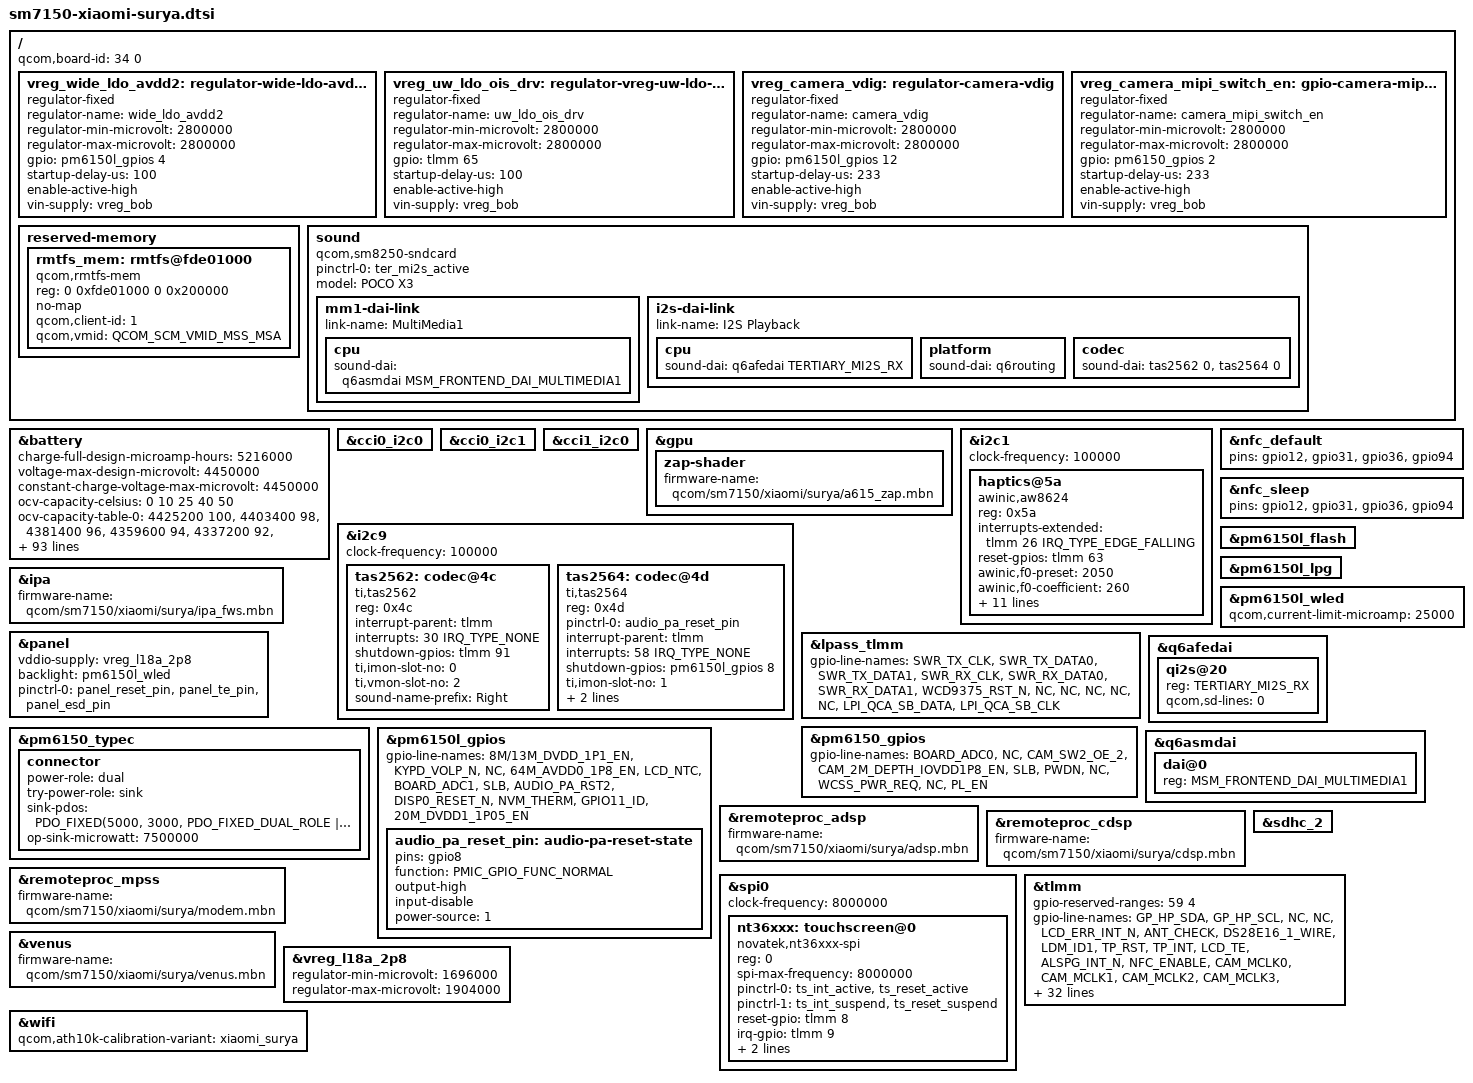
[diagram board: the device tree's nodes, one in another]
// SPDX-License-Identifier: BSD-3-Clause
/*
 * Copyright (c) 2024, Danila Tikhonov <danila@jiaxyga.com>
 * Copyright (c) 2024, David Wronek <davidwronek@gmail.com>
 */

/dts-v1/;

#include "sm7150-xiaomi-common.dtsi"

/ {
	qcom,board-id = <34 0>;

	vreg_wide_ldo_avdd2: regulator-wide-ldo-avdd2 {
		compatible = "regulator-fixed";
		regulator-name = "wide_ldo_avdd2";
		regulator-min-microvolt = <2800000>;
		regulator-max-microvolt = <2800000>;

		gpio = <&pm6150l_gpios 4 GPIO_ACTIVE_HIGH>;
		startup-delay-us = <100>;
		enable-active-high;

		vin-supply = <&vreg_bob>;
	};

	vreg_uw_ldo_ois_drv: regulator-vreg-uw-ldo-ois-drv {
		compatible = "regulator-fixed";
		regulator-name = "uw_ldo_ois_drv";
		regulator-min-microvolt = <2800000>;
		regulator-max-microvolt = <2800000>;

		gpio = <&tlmm 65 GPIO_ACTIVE_HIGH>;
		startup-delay-us = <100>;
		enable-active-high;

		vin-supply = <&vreg_bob>;
	};

	vreg_camera_vdig: regulator-camera-vdig {
		compatible = "regulator-fixed";
		regulator-name = "camera_vdig";
		regulator-min-microvolt = <2800000>;
		regulator-max-microvolt = <2800000>;

		gpio = <&pm6150l_gpios 12 GPIO_ACTIVE_HIGH>;
		startup-delay-us = <233>;
		enable-active-high;

		vin-supply = <&vreg_bob>;
	};

	vreg_camera_mipi_switch_en: gpio-camera-mipi-switch-en {
		compatible = "regulator-fixed";
		regulator-name = "camera_mipi_switch_en";
		regulator-min-microvolt = <2800000>;
		regulator-max-microvolt = <2800000>;

		gpio = <&pm6150_gpios 2 GPIO_ACTIVE_HIGH>;
		startup-delay-us = <233>;
		enable-active-high;

		vin-supply = <&vreg_bob>;
	};

	reserved-memory {
		rmtfs_mem: rmtfs@fde01000 {
			compatible = "qcom,rmtfs-mem";
			reg = <0 0xfde01000 0 0x200000>;
			no-map;

			qcom,client-id = <1>;
			qcom,vmid = <QCOM_SCM_VMID_MSS_MSA>;
		};
	};

	sound {
		compatible = "qcom,sm8250-sndcard";
		pinctrl-0 = <&ter_mi2s_active>;
		pinctrl-names = "default";
		model = "POCO X3";

		mm1-dai-link {
			link-name = "MultiMedia1";
			cpu {
				sound-dai = <&q6asmdai MSM_FRONTEND_DAI_MULTIMEDIA1>;
			};
		};

		i2s-dai-link {
			link-name = "I2S Playback";
			cpu {
				sound-dai = <&q6afedai TERTIARY_MI2S_RX>;
			};

			platform {
				sound-dai = <&q6routing>;
			};

			codec {
				sound-dai = <&tas2562 0>, <&tas2564 0>;
			};
		};
	};
};

&battery {
	/*
	 * ATL cell, "m703-pm7150b-atl-5160mah" profile of the downstream
	 * qpnp-qg battery data. The design capacity is the 25 degC entry of
	 * its fcc1-temp-lut, which Android also reports as design capacity.
	 */
	charge-full-design-microamp-hours = <5216000>;

	/*
	 * qcom,max-voltage-uv of the profile. Downstream only goes up to
	 * 4.48 V (qcom,ffc-max-voltage-uv) in its fast charging mode with
	 * the charge pump, which is not used here.
	 */
	voltage-max-design-microvolt = <4450000>;
	constant-charge-voltage-max-microvolt = <4450000>;

	/* pc-temp-v1-lut of the profile */
	ocv-capacity-celsius = <0 10 25 40 50>;
	/* 0 degC */
	ocv-capacity-table-0 = <4425200 100>, <4403400 98>, <4381400 96>, <4359600 94>,
				<4337200 92>, <4313600 90>, <4289400 88>, <4265400 86>,
				<4241200 84>, <4217400 82>, <4194300 80>, <4171700 78>,
				<4149400 76>, <4127400 74>, <4106000 72>, <4085800 70>,
				<4066300 68>, <4047000 66>, <4027800 64>, <4009000 62>,
				<3991200 60>, <3974500 58>, <3955700 56>, <3928800 54>,
				<3902600 52>, <3889400 50>, <3882000 48>, <3875300 46>,
				<3867600 44>, <3859900 42>, <3853000 40>, <3846400 38>,
				<3840400 36>, <3834600 34>, <3829200 32>, <3825000 30>,
				<3822000 28>, <3818600 26>, <3812600 24>, <3803300 22>,
				<3792600 20>, <3780100 18>, <3765600 16>, <3747800 14>,
				<3732900 12>, <3721400 10>, <3716700 9>, <3713600 8>,
				<3711000 7>, <3707300 6>, <3692100 5>, <3648400 4>,
				<3589400 3>, <3507400 2>, <3363900 1>, <3000000 0>;
	/* 10 degC */
	ocv-capacity-table-1 = <4432600 100>, <4411000 98>, <4389300 96>, <4367800 94>,
				<4346300 92>, <4323900 90>, <4300100 88>, <4275700 86>,
				<4251500 84>, <4227200 82>, <4203300 80>, <4179600 78>,
				<4156400 76>, <4134000 74>, <4112400 72>, <4091300 70>,
				<4070500 68>, <4050300 66>, <4032000 64>, <4015300 62>,
				<3996800 60>, <3973200 58>, <3948600 56>, <3928200 54>,
				<3910100 52>, <3895100 50>, <3883500 48>, <3873500 46>,
				<3863700 44>, <3854200 42>, <3846000 40>, <3838900 38>,
				<3832800 36>, <3827100 34>, <3822100 32>, <3817500 30>,
				<3813700 28>, <3809900 26>, <3804000 24>, <3795200 22>,
				<3784700 20>, <3772600 18>, <3758300 16>, <3740700 14>,
				<3724100 12>, <3713000 10>, <3710100 9>, <3708200 8>,
				<3705200 7>, <3702300 6>, <3681700 5>, <3636800 4>,
				<3576500 3>, <3492500 2>, <3350200 1>, <3000000 0>;
	/* 25 degC */
	ocv-capacity-table-2 = <4438400 100>, <4415100 98>, <4393200 96>, <4371500 94>,
				<4349600 92>, <4327600 90>, <4304400 88>, <4280100 86>,
				<4255600 84>, <4231100 82>, <4206700 80>, <4182700 78>,
				<4159000 76>, <4135700 74>, <4113200 72>, <4091400 70>,
				<4070500 68>, <4050300 66>, <4031200 64>, <4013800 62>,
				<3996400 60>, <3975200 58>, <3950600 56>, <3929000 54>,
				<3910900 52>, <3895200 50>, <3882100 48>, <3871000 46>,
				<3860800 44>, <3851000 42>, <3842200 40>, <3834500 38>,
				<3827600 36>, <3821500 34>, <3816300 32>, <3811500 30>,
				<3806700 28>, <3802000 26>, <3795700 24>, <3787300 22>,
				<3777200 20>, <3765500 18>, <3751700 16>, <3735000 14>,
				<3719100 12>, <3708700 10>, <3706000 9>, <3704400 8>,
				<3702400 7>, <3698500 6>, <3674900 5>, <3630400 4>,
				<3571000 3>, <3489500 2>, <3360800 1>, <3000000 0>;
	/* 40 degC */
	ocv-capacity-table-3 = <4440600 100>, <4415100 98>, <4392900 96>, <4371300 94>,
				<4349600 92>, <4328000 90>, <4305400 88>, <4281600 86>,
				<4257400 84>, <4233200 82>, <4208900 80>, <4184900 78>,
				<4161100 76>, <4137700 74>, <4115000 72>, <4093000 70>,
				<4071900 68>, <4051600 66>, <4032300 64>, <4014400 62>,
				<3996900 60>, <3976500 58>, <3953000 56>, <3931100 54>,
				<3911800 52>, <3894700 50>, <3881000 48>, <3869600 46>,
				<3859200 44>, <3849300 42>, <3840200 40>, <3832100 38>,
				<3824700 36>, <3817900 34>, <3812000 32>, <3806300 30>,
				<3800400 28>, <3794400 26>, <3787200 24>, <3778500 22>,
				<3768400 20>, <3756500 18>, <3742700 16>, <3726600 14>,
				<3712100 12>, <3702700 10>, <3700400 9>, <3698700 8>,
				<3697000 7>, <3692500 6>, <3665300 5>, <3620300 4>,
				<3561400 3>, <3480100 2>, <3352900 1>, <3000000 0>;
	/* 50 degC */
	ocv-capacity-table-4 = <4440800 100>, <4415600 98>, <4393300 96>, <4371600 94>,
				<4349900 92>, <4328200 90>, <4305800 88>, <4282400 86>,
				<4258600 84>, <4234600 82>, <4210400 80>, <4186500 78>,
				<4162800 76>, <4139500 74>, <4117000 72>, <4095000 70>,
				<4073900 68>, <4053300 66>, <4033600 64>, <4015300 62>,
				<3997600 60>, <3977500 58>, <3954900 56>, <3933500 54>,
				<3914000 52>, <3896300 50>, <3882100 48>, <3870300 46>,
				<3859500 44>, <3849200 42>, <3839900 40>, <3831200 38>,
				<3823200 36>, <3816000 34>, <3809600 32>, <3803400 30>,
				<3796200 28>, <3788300 26>, <3779900 24>, <3771500 22>,
				<3761900 20>, <3750000 18>, <3735900 16>, <3719500 14>,
				<3705100 12>, <3696200 10>, <3693900 9>, <3692300 8>,
				<3691100 7>, <3686600 6>, <3660900 5>, <3617800 4>,
				<3560500 3>, <3483500 2>, <3365900 1>, <3000000 0>;
};

&cci0_i2c0 {
	/* Sony IMX682 Main @ 50 */
};

&cci0_i2c1 {
	/* OmniVision ov02b1b Depth @ 50 */
};

&cci1_i2c0 {
	/* Samsung S5K3T2 Front @ ? */
	/* Sk Hynix Hi-259 Macro @ ? */
	/* Sk Hynix Hi-1337 Ultrawide @ ? */
};

&gpu {
	zap-shader {
		firmware-name = "qcom/sm7150/xiaomi/surya/a615_zap.mbn";
	};
};

&i2c1 {
	clock-frequency = <100000>;
	status = "okay";

	haptics@5a {
		compatible = "awinic,aw8624";
		reg = <0x5a>;
		interrupts-extended = <&tlmm 26 IRQ_TYPE_EDGE_FALLING>;
		reset-gpios = <&tlmm 63 GPIO_ACTIVE_HIGH>;

		awinic,f0-preset = <2050>;
		awinic,f0-coefficient = <260>;
		awinic,f0-calibration-percent = <7>;
		awinic,drive-level = <100>;

		awinic,f0-detection-play-time = <9>;
		awinic,f0-detection-wait-time = <5>;
		awinic,f0-detection-repeat = <1>;
		awinic,f0-detection-trace = <15>;

		awinic,boost-debug = /bits/ 8 <0x1b 0x1b 0x16>; // ?
		awinic,tset = /bits/ 8 <0x11>;
		awinic,r-spare = /bits/ 8 <0x68>;

		awinic,bemf-upper-threshold = <4000>; // ?
		awinic,bemf-lower-threshold = <2500>; // ?
	};
};

&i2c9 {
	clock-frequency = <100000>;
	status = "okay";

	/* ovti,wl2866d (cam regulator) @ 28 */

	tas2562: codec@4c { /* SPK */
		compatible = "ti,tas2562";
		reg = <0x4c>;
		#sound-dai-cells = <1>;
		interrupt-parent = <&tlmm>;
		interrupts = <30 IRQ_TYPE_NONE>;
		shutdown-gpios = <&tlmm 91 GPIO_ACTIVE_HIGH>;
		ti,imon-slot-no = <0>;
		ti,vmon-slot-no = <2>;
		sound-name-prefix = "Right";
	};

	tas2564: codec@4d { /* EAR */
		compatible = "ti,tas2564";
		reg = <0x4d>;
		#sound-dai-cells = <1>;
		pinctrl-names = "default";
		pinctrl-0 = <&audio_pa_reset_pin>;
		interrupt-parent = <&tlmm>;
		interrupts = <58 IRQ_TYPE_NONE>;
		shutdown-gpios = <&pm6150l_gpios 8 GPIO_ACTIVE_HIGH>;
		ti,imon-slot-no = <1>;
		ti,vmon-slot-no = <3>;
		sound-name-prefix = "Left";
	};

	/* ti,bq25968 (charger) @ 65 */
};

&ipa {
	firmware-name = "qcom/sm7150/xiaomi/surya/ipa_fws.mbn";
};

&lpass_tlmm {
	gpio-line-names = "SWR_TX_CLK", /* GPIO_0 */
			  "SWR_TX_DATA0",
			  "SWR_TX_DATA1",
			  "SWR_RX_CLK",
			  "SWR_RX_DATA0",
			  "SWR_RX_DATA1",
			  "WCD9375_RST_N",
			  "NC",
			  "NC",
			  "NC",
			  "NC", /* GPIO_10 */
			  "NC",
			  "LPI_QCA_SB_DATA",
			  "LPI_QCA_SB_CLK";
};

&nfc_default {
	pins = "gpio12", "gpio31", "gpio36", "gpio94";
};

&nfc_sleep {
	pins = "gpio12", "gpio31", "gpio36", "gpio94";
};

&panel {
	vddio-supply = <&vreg_l18a_2p8>;
	/delete-property/ vdd3p3-supply;

	backlight = <&pm6150l_wled>;

	pinctrl-0 = <&panel_reset_pin &panel_te_pin &panel_esd_pin>;
};

&pm6150_gpios {
	gpio-line-names = "BOARD_ADC0", /* GPIO_1 */
			  "NC",
			  "CAM_SW2_OE_2",
			  "CAM_2M_DEPTH_IOVDD1P8_EN",
			  "SLB",
			  "PWDN",
			  "NC",
			  "WCSS_PWR_REQ",
			  "NC",
			  "PL_EN"; /* GPIO_10 */
};

&pm6150_typec {
	connector {
		/*
		 * The port is the only way to charge the phone, so it has to
		 * be able to sink. Prefer the sink role when attached to
		 * another dual-role port. Only 5 V is requested: higher input
		 * voltages are only useful with the BQ2597x charge pump, which
		 * is not supported.
		 */
		power-role = "dual";
		try-power-role = "sink";

		sink-pdos = <PDO_FIXED(5000, 3000, PDO_FIXED_DUAL_ROLE |
			     PDO_FIXED_USB_COMM | PDO_FIXED_DATA_SWAP)>;
		/* 5 V at the 1.5 A input current limit of the charger */
		op-sink-microwatt = <7500000>;
	};
};

&pm6150l_flash {
	status = "okay";
};

&pm6150l_gpios {
	gpio-line-names = "8M/13M_DVDD_1P1_EN", /* GPIO_1 */
			  "KYPD_VOLP_N",
			  "NC",
			  "64M_AVDD0_1P8_EN",
			  "LCD_NTC",
			  "BOARD_ADC1",
			  "SLB",
			  "AUDIO_PA_RST2",
			  "DISP0_RESET_N",
			  "NVM_THERM", /* GPIO_10 */
			  "GPIO11_ID",
			  "20M_DVDD1_1P05_EN";

	audio_pa_reset_pin: audio-pa-reset-state {
		pins = "gpio8";
		function = PMIC_GPIO_FUNC_NORMAL;
		output-high;
		input-disable;
		power-source = <1>;
	};
};

&pm6150l_lpg {
	status = "okay";
};

&pm6150l_wled {
	qcom,current-limit-microamp = <25000>;

	status = "okay";
};

&q6afedai {
	qi2s@20 {
		reg = <TERTIARY_MI2S_RX>;
		qcom,sd-lines = <0>;
	};
};

&q6asmdai {
	dai@0 {
		reg = <MSM_FRONTEND_DAI_MULTIMEDIA1>;
	};
};

&remoteproc_adsp {
	firmware-name = "qcom/sm7150/xiaomi/surya/adsp.mbn";
};

&remoteproc_cdsp {
	firmware-name = "qcom/sm7150/xiaomi/surya/cdsp.mbn";
};

&remoteproc_mpss {
	firmware-name = "qcom/sm7150/xiaomi/surya/modem.mbn";
};

&sdhc_2 {
	status = "okay";
};

&spi0 {
	clock-frequency = <8000000>;
	status = "okay";

	nt36xxx: touchscreen@0 {
		compatible = "novatek,nt36xxx-spi";
		reg = <0>;

		spi-max-frequency = <8000000>;

		pinctrl-0 = <&ts_int_active &ts_reset_active>;
		pinctrl-1 = <&ts_int_suspend &ts_reset_suspend>;
		pinctrl-names = "default", "sleep";

		reset-gpio = <&tlmm 8 GPIO_ACTIVE_HIGH>;
		irq-gpio = <&tlmm 9 IRQ_TYPE_EDGE_FALLING>;

		vio-supply = <&vreg_l18a_2p8>;

		panel = <&panel>;
	};
};

&tlmm {
	/* Reserved I/Os for FP */
	gpio-reserved-ranges = <59 4>;

	gpio-line-names = "GP_HP_SDA", /* GPIO_0 */
			  "GP_HP_SCL",
			  "NC",
			  "NC",
			  "LCD_ERR_INT_N",
			  "ANT_CHECK",
			  "DS28E16_1_WIRE",
			  "LDM_ID1",
			  "TP_RST",
			  "TP_INT",
			  "LCD_TE", /* GPIO_10 */
			  "ALSPG_INT_N",
			  "NFC_ENABLE",
			  "CAM_MCLK0",
			  "CAM_MCLK1",
			  "CAM_MCLK2",
			  "CAM_MCLK3",
			  "CC_I2C_SDA0",
			  "CC_I2C_SCL0",
			  "CC_I2C_SDA1",
			  "CC_I2C_SCL1", /* GPIO_20 */
			  "CLK_BUFFER_2",
			  "NC",
			  "CAM4_RST_N",
			  "CAM3_RST_N",
			  "CAM1_RST_N",
			  "HAPTIC_INT_N",
			  "CC_I2C_SDA2",
			  "CC_I2C_SCL2",
			  "NC",
			  "AUDIO_INT1",  /* GPIO_30 */
			  "NFC_CLK_REQ",
			  "CLK_BUFFER_3",
			  "CLK_BUFFER_4",
			  "NFC_I2C_SDA",
			  "NFC_I2C_SCL",
			  "NFC_DWL_REQ",
			  "NFC_IRQ",
			  "BT_UART_CTS",
			  "BT_UART_RFR",
			  "BT_UART_TX", /* GPIO_40 */
			  "BT_UART_RX",
			  "SVDD_PWR_REQ",
			  "CHARGER_INT",
			  "DBG_UART_TX",
			  "DBG_UART_RX",
			  "AUDIO_I2C_SDA",
			  "AUDIO_I2C_SCL",
			  "FORCE_USB_BOOT",
			  "TS_SPI_MISO",
			  "TS_SPI_MOSI", /* GPIO_50 */
			  "TS_SPI_CLK",
			  "TS_SPI_CS_N",
			  "LPI_MI2S_1_SCK",
			  "LPI_MI2S_1_WS",
			  "LPI_MI2S_1_DATA0",
			  "LPI_MI2S_1_DATA1",
			  "CHIP_EN",
			  "AUDIO_INT2",
			  "FP_SPI_MISO",
			  "FP_SPI_MOSI", /* GPIO_60 */
			  "FP_SPI_CLK",
			  "FP_SPI_CS",
			  "HAPTIC_RST_N",
			  "CAM5_RST_N",
			  "DRV_VDD2P8_EN",
			  "64M_AF_EN",
			  "SAR_CAP_INI",
			  "CLK_BUFFER_1",
			  "SD_CARD_DET_N",
			  "NC", /* GPIO_70 */
			  "LDM_IDO",
			  "CAM0_RST_N",
			  "WLAN_SW_CTRL",
			  "PRX_TUNER_SW3",
			  "UIM2_DATA",
			  "UIM2_CLK",
			  "UIM2_RESET",
			  "UIM2_PRESENT",
			  "UIM1_DATA",
			  "UIM1_CLK", /* GPIO_80 */
			  "UIM1_RESET",
			  "UIM1_PRESENT",
			  "PRX_TUNER_SW1",
			  "ANT_CHECK_DIV",
			  "WMSS_RESET_N",
			  "GINT1",
			  "GINT2",
			  "8M_AFVDD_2P8_EN",
			  "FP_INT_N",
			  "FP_RESET_N", /* GPIO_90 */
			  "AUDIO_PA_RST1",
			  "NC",
			  "CAM2_RST_N",
			  "SWITCH_SEL1",
			  "DPDT_TUNER_SW",
			  "QLINK_REQUEST",
			  "QLINK_ENABLE",
			  "LNA_PRX_B1_EN",
			  "DRX_TUNER_SW4",
			  "DRX_ANT_EN", /* GPIO_100 */
			  "NC",
			  "IR_EN_SPI_MOSI",
			  "NC",
			  "USB_PHY_PS",
			  "RFFE5_DATA",
			  "RFFE5_CLK",
			  "LNA_DRX_B7B38B41_EN_v2",
			  "MSS_LTE_COXM_TXD",
			  "MSS_LTE_COXM_RXD",
			  "RFFE2_DATA", /* GPIO_110 */
			  "RFFE2_CLK",
			  "RFFE1_DATA",
			  "RFFE1_CLK";
};

&venus {
	firmware-name = "qcom/sm7150/xiaomi/surya/venus.mbn";
};

&vreg_l18a_2p8 {
	regulator-min-microvolt = <1696000>;
	regulator-max-microvolt = <1904000>;
};

&wifi {
	qcom,ath10k-calibration-variant = "xiaomi_surya";
};
